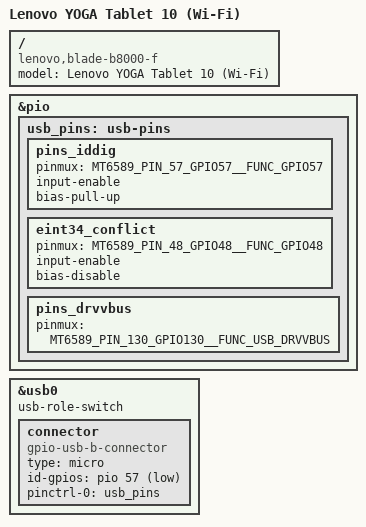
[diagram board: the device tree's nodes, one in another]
// SPDX-License-Identifier: GPL-2.0+
/*
 * Copyright (c) 2025 akku <akkun11.open@gmail.com>
 */

#include <dt-bindings/gpio/gpio.h>
#include <dt-bindings/pinctrl/mt6589-pinfunc.h>

#include "mt6589-lenovo-blade.dtsi"

/ {
	model = "Lenovo YOGA Tablet 10 (Wi-Fi)";
	compatible = "lenovo,blade-b8000-f", "lenovo,blade", "mediatek,mt6589";
};

&pio {
	usb_pins: usb-pins {
		pins_iddig {
			pinmux = <MT6589_PIN_57_GPIO57__FUNC_GPIO57>;
			input-enable;
			bias-pull-up;
		};

		eint34_conflict {
			pinmux = <MT6589_PIN_48_GPIO48__FUNC_GPIO48>;
			input-enable;
			bias-disable;
		};

		pins_drvvbus {
			pinmux = <MT6589_PIN_130_GPIO130__FUNC_USB_DRVVBUS>;
		};
	};
};

&usb0 {
	status = "okay";
	usb-role-switch;

	connector {
		compatible = "gpio-usb-b-connector", "usb-b-connector";
		type = "micro";
		id-gpios = <&pio 57 GPIO_ACTIVE_LOW>;
		pinctrl-names = "default";
		pinctrl-0 = <&usb_pins>;
	};
};
